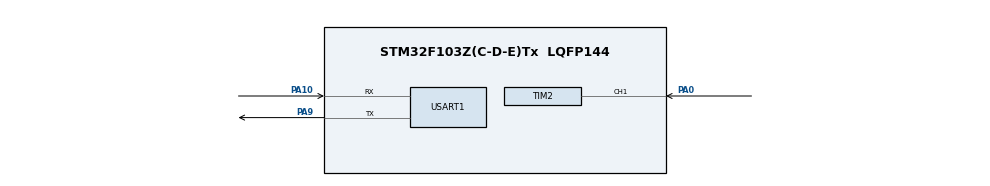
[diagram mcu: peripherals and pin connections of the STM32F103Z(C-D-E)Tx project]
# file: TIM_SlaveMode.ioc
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Mcu.Family=STM32F1
Mcu.Name=STM32F103Z(C-D-E)Tx
Mcu.Package=LQFP144
NVIC.PriorityGroup=NVIC_PRIORITYGROUP_4
NVIC.TIM2_IRQn=true\:0\:0\:false\:false\:true\:true\:true\:true
OSC_IN.Mode=HSE-External-Oscillator
OSC_IN.Signal=RCC_OSC_IN
OSC_OUT.Mode=HSE-External-Oscillator
OSC_OUT.Signal=RCC_OSC_OUT
PA0-WKUP.Signal=S_TIM2_CH1_ETR
PA10.Mode=Asynchronous
PA10.Signal=USART1_RX
PA13.Mode=Serial_Wire
PA13.Signal=SYS_JTMS-SWDIO
PA14.Mode=Serial_Wire
PA14.Signal=SYS_JTCK-SWCLK
PA9.Mode=Asynchronous
PA9.Signal=USART1_TX
ProjectManager.HeapSize=0x200
ProjectManager.StackSize=0x400
ProjectManager.TargetToolchain=CMake
RCC.APB1Freq_Value=8000000
RCC.APB2Freq_Value=8000000
SH.S_TIM2_CH1_ETR.0=TIM2_CH1,TriggerSource_TI1FP1
TIM2.Period=5000 - 1
TIM2.Prescaler=8000 - 1
TIM2.Slave_TriggerFilter=15
USART1.VirtualMode=VM_ASYNC
VP_TIM2_VS_ClockSourceINT.Mode=Internal
VP_TIM2_VS_ControllerModeReset.Mode=Reset Mode
board=custom

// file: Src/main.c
/* USER CODE BEGIN Header */
/**
 ******************************************************************************
 * @file           : main.c
 * @brief          : Main program body
 ******************************************************************************
 * @attention
 *
 * Copyright (c) 2025 STMicroelectronics.
 * All rights reserved.
 *
 * This software is licensed under terms that can be found in the LICENSE file
 * in the root directory of this software component.
 * If no LICENSE file comes with this software, it is provided AS-IS.
 *
 ******************************************************************************
 */
/* USER CODE END Header */
#include "main.h"

#include "gpio.h"
#include "stm32f1xx.h"
#include "stm32f1xx_hal_tim.h"
#include "stm32f1xx_hal_uart.h"
#include "tim.h"
#include "usart.h"

/* USER CODE BEGIN Includes */
#include <stdint.h>
#include <stdio.h>

/* USER CODE END Includes */

/* USER CODE BEGIN PV */
int counter = 0;
char message[50] = "";
/* USER CODE END PV */

void SystemClock_Config(void);

/* USER CODE BEGIN 0 */
// 定时器更新中断
// 自动重装载寄存器和从模式控制器（复位模式）都会触发更新中断，将更新中断标志位置 1
// 从模式控制器在接收到触发信号时，还会设置一个触发器中断标志位
char updateMsg[] = "自动重装载\r\n";
char triggerMsg[] = "从模式触发\r\n";
void HAL_TIM_PeriodElapsedCallback(TIM_HandleTypeDef* htim) {
    if (htim->Instance == TIM2) {
        if (__HAL_TIM_GET_FLAG(htim, TIM_FLAG_TRIGGER) == SET) {
            // HAL 库并未将触发器中断标志位清除，所以我们需要手动清除
            __HAL_TIM_CLEAR_FLAG(htim, TIM_FLAG_TRIGGER);
            HAL_UART_Transmit(&huart1, (uint8_t*) triggerMsg, sizeof(triggerMsg), 100);
        } else {
            HAL_UART_Transmit(&huart1, (uint8_t*) updateMsg, sizeof(updateMsg), 100);
        }
    }
}
/* USER CODE END 0 */

int main(void) {

    /* MCU Configuration--------------------------------------------------------*/

    /* Reset of all peripherals, Initializes the Flash interface and the Systick. */
    HAL_Init();

    /* Configure the system clock */
    SystemClock_Config();

    /* Initialize all configured peripherals */
    MX_GPIO_Init();
    MX_TIM2_Init();
    MX_USART1_UART_Init();
    /* USER CODE BEGIN 2 */
    // __HAL_TIM_CLEAR_FLAG(&htim2, TIM_FLAG_UPDATE);
    __HAL_TIM_CLEAR_IT(&htim2, TIM_FLAG_UPDATE);
    HAL_TIM_Base_Start_IT(&htim2); // Start the timer interrupt
    /* USER CODE END 2 */

    /* Infinite loop */
    /* USER CODE BEGIN WHILE */
    while (1) {
        // Get the current counter value
        counter = __HAL_TIM_GET_COUNTER(&htim2);
        sprintf(message, "Counter: %d\r\n", counter);
        HAL_UART_Transmit(&huart1, (uint8_t*) message, sizeof(message), 100);

        HAL_Delay(500 - 5);
        /* USER CODE END WHILE */

    }
}

void SystemClock_Config(void) {
    RCC_OscInitTypeDef RCC_OscInitStruct = {0};
    RCC_ClkInitTypeDef RCC_ClkInitStruct = {0};

    /** Initializes the RCC Oscillators according to the specified parameters
     * in the RCC_OscInitTypeDef structure.
     */
    RCC_OscInitStruct.OscillatorType = RCC_OSCILLATORTYPE_HSI;
    RCC_OscInitStruct.HSIState = RCC_HSI_ON;
    RCC_OscInitStruct.HSICalibrationValue = RCC_HSICALIBRATION_DEFAULT;
    RCC_OscInitStruct.PLL.PLLState = RCC_PLL_NONE;
    if (HAL_RCC_OscConfig(&RCC_OscInitStruct) != HAL_OK) {
        Error_Handler();
    }

    /** Initializes the CPU, AHB and APB buses clocks
     */
    RCC_ClkInitStruct.ClockType = RCC_CLOCKTYPE_HCLK | RCC_CLOCKTYPE_SYSCLK | RCC_CLOCKTYPE_PCLK1 | RCC_CLOCKTYPE_PCLK2;
    RCC_ClkInitStruct.SYSCLKSource = RCC_SYSCLKSOURCE_HSI;
    RCC_ClkInitStruct.AHBCLKDivider = RCC_SYSCLK_DIV1;
    RCC_ClkInitStruct.APB1CLKDivider = RCC_HCLK_DIV1;
    RCC_ClkInitStruct.APB2CLKDivider = RCC_HCLK_DIV1;

    if (HAL_RCC_ClockConfig(&RCC_ClkInitStruct, FLASH_LATENCY_0) != HAL_OK) {
        Error_Handler();
    }
}

void Error_Handler(void) {
    __disable_irq();
    while (1) {}
}
